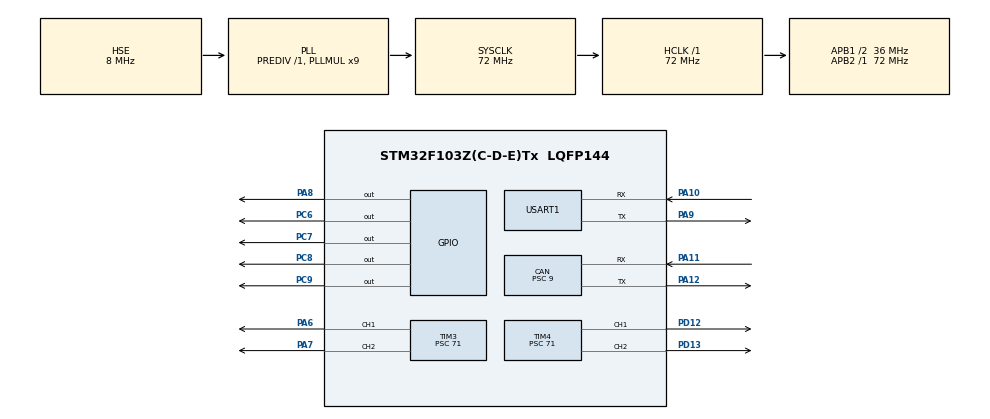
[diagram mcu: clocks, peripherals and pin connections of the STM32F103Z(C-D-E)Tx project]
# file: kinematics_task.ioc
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CAN.BS1=CAN_BS1_5TQ
CAN.BS2=CAN_BS2_2TQ
CAN.CalculateBaudRate=500000
CAN.CalculateTimeBit=2000
CAN.CalculateTimeQuantum=250.0
CAN.Prescaler=9
Dma.Request0=USART1_RX
Dma.Request1=USART1_TX
Dma.USART1_RX.0.Direction=DMA_PERIPH_TO_MEMORY
Dma.USART1_RX.0.Instance=DMA1_Channel5
Dma.USART1_RX.0.MemDataAlignment=DMA_MDATAALIGN_BYTE
Dma.USART1_RX.0.MemInc=DMA_MINC_ENABLE
Dma.USART1_RX.0.Mode=DMA_NORMAL
Dma.USART1_RX.0.PeriphDataAlignment=DMA_PDATAALIGN_BYTE
Dma.USART1_RX.0.PeriphInc=DMA_PINC_DISABLE
Dma.USART1_RX.0.Priority=DMA_PRIORITY_LOW
Dma.USART1_TX.1.Direction=DMA_MEMORY_TO_PERIPH
Dma.USART1_TX.1.Instance=DMA1_Channel4
Dma.USART1_TX.1.MemDataAlignment=DMA_MDATAALIGN_BYTE
Dma.USART1_TX.1.MemInc=DMA_MINC_ENABLE
Dma.USART1_TX.1.Mode=DMA_NORMAL
Dma.USART1_TX.1.PeriphDataAlignment=DMA_PDATAALIGN_BYTE
Dma.USART1_TX.1.PeriphInc=DMA_PINC_DISABLE
Dma.USART1_TX.1.Priority=DMA_PRIORITY_LOW
FREERTOS.HEAP_NUMBER=4
FREERTOS.INCLUDE_eTaskGetState=1
FREERTOS.INCLUDE_uxTaskGetStackHighWaterMark=1
FREERTOS.INCLUDE_vTaskDelayUntil=1
FREERTOS.INCLUDE_xQueueGetMutexHolder=1
FREERTOS.INCLUDE_xSemaphoreGetMutexHolder=1
FREERTOS.INCLUDE_xTimerPendFunctionCall=1
FREERTOS.Tasks01=defaultTask,0,128,StartDefaultTask,Default,NULL,Dynamic,NULL,NULL
FREERTOS.configTOTAL_HEAP_SIZE=20000
FREERTOS.configUSE_COUNTING_SEMAPHORES=1
FREERTOS.configUSE_RECURSIVE_MUTEXES=1
FREERTOS.configUSE_TIMERS=1
FREERTOS.configUSE_TRACE_FACILITY=1
Mcu.Family=STM32F1
Mcu.Name=STM32F103Z(C-D-E)Tx
Mcu.Package=LQFP144
Mcu.UserConstants=PI,3.1415926
NVIC.DMA1_Channel4_IRQn=true\:5\:0\:false\:false\:true\:true\:false\:true\:true
NVIC.DMA1_Channel5_IRQn=true\:5\:0\:false\:false\:true\:true\:false\:true\:true
NVIC.PriorityGroup=NVIC_PRIORITYGROUP_4
NVIC.TIM3_IRQn=true\:5\:0\:false\:false\:true\:true\:true\:true\:true
NVIC.TIM4_IRQn=true\:5\:0\:false\:false\:true\:true\:true\:true\:true
NVIC.TIM7_IRQn=true\:15\:0\:false\:false\:true\:false\:false\:true\:true
NVIC.TimeBase=TIM7_IRQn
NVIC.TimeBaseIP=TIM7
NVIC.USART1_IRQn=true\:5\:0\:false\:false\:true\:true\:true\:true\:true
OSC_IN.Mode=HSE-External-Oscillator
OSC_IN.Signal=RCC_OSC_IN
OSC_OUT.Mode=HSE-External-Oscillator
OSC_OUT.Signal=RCC_OSC_OUT
PA10.Mode=Asynchronous
PA10.Signal=USART1_RX
PA11.Mode=CAN_Activate
PA11.Signal=CAN_RX
PA12.Mode=CAN_Activate
PA12.Signal=CAN_TX
PA13.Mode=Serial_Wire
PA13.Signal=SYS_JTMS-SWDIO
PA14.Mode=Serial_Wire
PA14.Signal=SYS_JTCK-SWCLK
PA6.Signal=S_TIM3_CH1
PA7.Signal=S_TIM3_CH2
PA8.Signal=GPIO_Output
PA9.Mode=Asynchronous
PA9.Signal=USART1_TX
PC6.Signal=GPIO_Output
PC7.Signal=GPIO_Output
PC8.Signal=GPIO_Output
PC9.Signal=GPIO_Output
PD12.Signal=S_TIM4_CH1
PD13.Signal=S_TIM4_CH2
ProjectManager.HeapSize=0x200
ProjectManager.StackSize=0x400
ProjectManager.TargetToolchain=MDK-ARM V5.32
RCC.AHBFreq_Value=72000000
RCC.APB1CLKDivider=RCC_HCLK_DIV2
RCC.APB1Freq_Value=36000000
RCC.APB1TimFreq_Value=72000000
RCC.APB2Freq_Value=72000000
RCC.APB2TimFreq_Value=72000000
RCC.HCLKFreq_Value=72000000
RCC.PLLMUL=RCC_PLL_MUL9
RCC.PLLSourceVirtual=RCC_PLLSOURCE_HSE
RCC.SYSCLKFreq_VALUE=72000000
RCC.SYSCLKSource=RCC_SYSCLKSOURCE_PLLCLK
RCC.USBFreq_Value=72000000
SH.S_TIM3_CH1.0=TIM3_CH1,PWM Generation1 CH1
SH.S_TIM3_CH2.0=TIM3_CH2,PWM Generation2 CH2
SH.S_TIM4_CH1.0=TIM4_CH1,PWM Generation1 CH1
SH.S_TIM4_CH2.0=TIM4_CH2,PWM Generation2 CH2
TIM3.Channel-PWM\ Generation1\ CH1=TIM_CHANNEL_1
TIM3.Channel-PWM\ Generation2\ CH2=TIM_CHANNEL_2
TIM3.Period=199
TIM3.Prescaler=71
TIM3.Pulse-PWM\ Generation1\ CH1=100
TIM3.Pulse-PWM\ Generation2\ CH2=100
TIM4.Channel-PWM\ Generation1\ CH1=TIM_CHANNEL_1
TIM4.Channel-PWM\ Generation2\ CH2=TIM_CHANNEL_2
TIM4.Period=199
TIM4.Prescaler=71
TIM4.Pulse-PWM\ Generation1\ CH1=100
TIM4.Pulse-PWM\ Generation2\ CH2=100
USART1.VirtualMode=VM_ASYNC
VP_FREERTOS_VS_CMSIS_V1.Mode=CMSIS_V1
VP_SYS_VS_tim7.Mode=TIM7
VP_TIM3_VS_ClockSourceINT.Mode=Internal
VP_TIM4_VS_ClockSourceINT.Mode=Internal
board=custom

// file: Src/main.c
/* USER CODE BEGIN Header */
/**
  ******************************************************************************
  * @file           : main.c
  * @brief          : Main program body
  ******************************************************************************
  * @attention
  *
  * Copyright (c) 2024 STMicroelectronics.
  * All rights reserved.
  *
  * This software is licensed under terms that can be found in the LICENSE file
  * in the root directory of this software component.
  * If no LICENSE file comes with this software, it is provided AS-IS.
  *
  ******************************************************************************
  */
/* USER CODE END Header */
#include "main.h"
#include "cmsis_os.h"
#include "can.h"
#include "dma.h"
#include "tim.h"
#include "usart.h"
#include "gpio.h"

/* USER CODE BEGIN Includes */
#include <stdio.h>
/* USER CODE END Includes */

void SystemClock_Config(void);
void MX_FREERTOS_Init(void);

int main(void)
{

  /* MCU Configuration--------------------------------------------------------*/

  /* Reset of all peripherals, Initializes the Flash interface and the Systick. */
  HAL_Init();

  /* Configure the system clock */
  SystemClock_Config();

  /* Initialize all configured peripherals */
  MX_GPIO_Init();
  MX_DMA_Init();
  MX_USART1_UART_Init();
  MX_CAN_Init();
  MX_TIM4_Init();
  MX_TIM3_Init();
  /* USER CODE BEGIN 2 */
	CAN_Init();
	StartUART1Recv();

  /* USER CODE END 2 */

  /* Call init function for freertos objects (in cmsis_os2.c) */
  MX_FREERTOS_Init();

  /* Start scheduler */
  osKernelStart();

  /* We should never get here as control is now taken by the scheduler */

  /* Infinite loop */
  while (1)
  {

  }
}

void SystemClock_Config(void)
{
  RCC_OscInitTypeDef RCC_OscInitStruct = {0};
  RCC_ClkInitTypeDef RCC_ClkInitStruct = {0};

  /** Initializes the RCC Oscillators according to the specified parameters
  * in the RCC_OscInitTypeDef structure.
  */
  RCC_OscInitStruct.OscillatorType = RCC_OSCILLATORTYPE_HSE;
  RCC_OscInitStruct.HSEState = RCC_HSE_ON;
  RCC_OscInitStruct.HSEPredivValue = RCC_HSE_PREDIV_DIV1;
  RCC_OscInitStruct.HSIState = RCC_HSI_ON;
  RCC_OscInitStruct.PLL.PLLState = RCC_PLL_ON;
  RCC_OscInitStruct.PLL.PLLSource = RCC_PLLSOURCE_HSE;
  RCC_OscInitStruct.PLL.PLLMUL = RCC_PLL_MUL9;
  if (HAL_RCC_OscConfig(&RCC_OscInitStruct) != HAL_OK)
  {
    Error_Handler();
  }

  /** Initializes the CPU, AHB and APB buses clocks
  */
  RCC_ClkInitStruct.ClockType = RCC_CLOCKTYPE_HCLK|RCC_CLOCKTYPE_SYSCLK
                              |RCC_CLOCKTYPE_PCLK1|RCC_CLOCKTYPE_PCLK2;
  RCC_ClkInitStruct.SYSCLKSource = RCC_SYSCLKSOURCE_PLLCLK;
  RCC_ClkInitStruct.AHBCLKDivider = RCC_SYSCLK_DIV1;
  RCC_ClkInitStruct.APB1CLKDivider = RCC_HCLK_DIV2;
  RCC_ClkInitStruct.APB2CLKDivider = RCC_HCLK_DIV1;

  if (HAL_RCC_ClockConfig(&RCC_ClkInitStruct, FLASH_LATENCY_2) != HAL_OK)
  {
    Error_Handler();
  }
}

void HAL_TIM_PeriodElapsedCallback(TIM_HandleTypeDef *htim)
{
  if (htim->Instance == TIM7) {
    HAL_IncTick();
  }
}

void Error_Handler(void)
{
  __disable_irq();
  while (1)
  {
  }
}
